# AC784x register map
Vendor: AutoChips; Series: AC78; File version: 1.0
CPU: CM4 r0p1, little endian, MPU, FPU, VTOR, 4 interrupt priority bits
Registers are 32-bit, read-write, reset 0x0 unless marked. A register's access mark holds for its fields unless they carry their own. Offsets are from the block's base; [hi:lo] are bit positions; {n}, {i} and the like mark numbered series.

## DMA0_TOP_RST — DMA0 All Channnels Share The Registers
Base 0x40012000
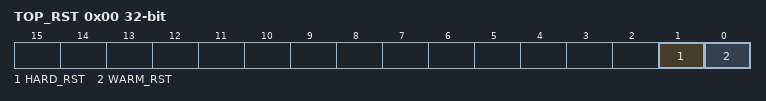
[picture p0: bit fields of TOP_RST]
0x00 TOP_RST reset not defined
  [1] HARD_RST — hard reset
    0=Disable; 1=Enable
  [0] WARM_RST — warm reset
    0=Disable; 1=Enable

## DMA0_Channel0 — DMA channel
Base 0x40012040
Same registers: DMA0_Channel{n} {0x40012040+0x40*n} (n=1..15)
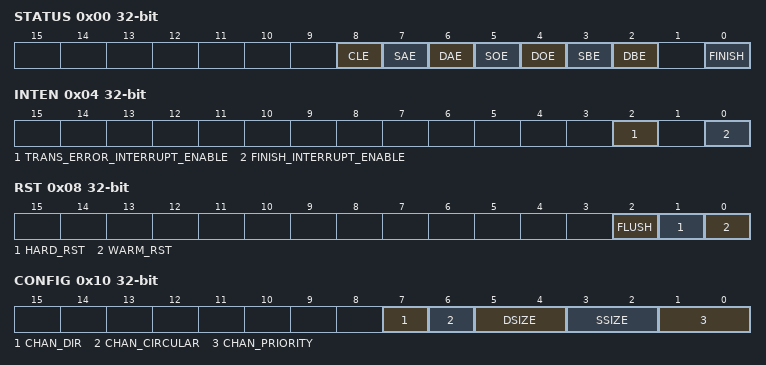
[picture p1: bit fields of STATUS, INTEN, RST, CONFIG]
0x00 STATUS reset not defined
  [8] CLE — Channel Length Error
    0=No channel length configuration error; 1=Channel length configuration error
  [7] SAE — Source Address Error
    0=No source address configuration error; 1=Source address configuration error
  [6] DAE — Destination Address Error
    0=No destination address configuration error; 1=Destination address configuration error
  [5] SOE — Source Offset Error
    0=No source offset configuration error; 1=Source offset configuration error
  [4] DOE — Destination Offset Error
    0=No destination offset configuration error; 1=Destination offset configuration error
  [3] SBE — Source Bus Error
    0=No source bus error; 1=Source bus error
  [2] DBE — Destination Bus Error
    0=No destination bus error; 1=Destination bus error
  [0] FINISH — transfer finished flag
    0=Transfer not finish; 1=Transfer finished
0x04 INTEN reset not defined — Interrupt Enable Register
  [2] TRANS_ERROR_INTERRUPT_ENABLE — transfer error interrupt enable or disable
    0=Disable; 1=Enable
  [0] FINISH_INTERRUPT_ENABLE — transfer finished interrupt enable or disable
    0=Disable; 1=Enable
0x08 RST reset not defined — Reset Register
  [all] fields
    0=Disable; 1=Enable
  [2] FLUSH — dma flush enable or disable
  [1] HARD_RST — hard reset enable or disable
  [0] WARM_RST — warm reset enable or disable
0x0C STOP reset not defined
  [0] STOP — DMA channel stop enable or disable
    0=Not stop channel transfer; 1=Stop channel transfer
0x10 CONFIG reset not defined — DMA Config Register
  [7] CHAN_DIR — channel read data direction select
    0=DMA read from peripheral; 1=DMA read from memory
  [6] CHAN_CIRCULAR — channel circular mode enable or disable
    0=Disable; 1=Enable
  [5:4] DSIZE — Destination size select
    0=8 bits; 1=16 bits; 2=32 bits
  [3:2] SSIZE — Source size select
    0=8 bits; 1=16 bits; 2=32 bits
  [1:0] CHAN_PRIORITY — channel priority select
    0=DMA channel priority low; 1=DMA channel priority medium; 2=DMA channel priority high; 3=DMA channel priority very high
0x14 CHAN_LENGTH reset not defined — Channel Length Register
  [15:0] CHAN_LENGTH — DMA channel transfer length
0x18 SSTART_ADDR reset not defined — Source Start Address Register
  [31:0] SSTART_ADDR — Source start address
0x1C SEND_ADDR reset not defined — Source End Address Register
  [31:0] SEND_ADDR — set source end address
0x20 DSTART_ADDR reset not defined — Destination Start Address Register
  [31:0] DSTART_ADDR — set destination start address
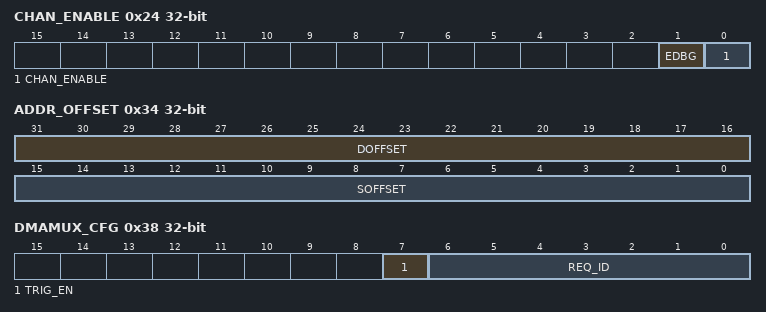
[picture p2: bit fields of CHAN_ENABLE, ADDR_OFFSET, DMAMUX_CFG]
0x24 CHAN_ENABLE reset not defined — Channel Enable Register
  [1] EDBG — debug enable
    0=DMA continues to operate in debug mode; 1=DMA will be paused in debug mode
  [0] CHAN_ENABLE — channel enable
    0=Disable; 1=Enable
0x28 DATA_TRANS_NUM reset not defined — Data Transfer Number Register
  [15:0] DATA_TRANS_NUM — data has been transfered number
0x2C FIFO_LEFT_NUM reset not defined — Internal FIFO Data Left Number Register
  [5:0] FIFO_LEFT_NUM — internal fifo data left number
0x30 DEND_ADDR reset not defined — Destination End Address Register
  [31:0] DEND_ADDR — set destination end address
0x34 ADDR_OFFSET reset not defined — Address Offset Register
  [31:16] DOFFSET — set destination address offset
  [15:0] SOFFSET — set source address offset
0x38 DMAMUX_CFG reset not defined — DMAMUX Configuration Register
  [7] TRIG_EN — Trigger enable
    0=Disable; 1=Enable
  [6:0] REQ_ID — peripheral request ID
